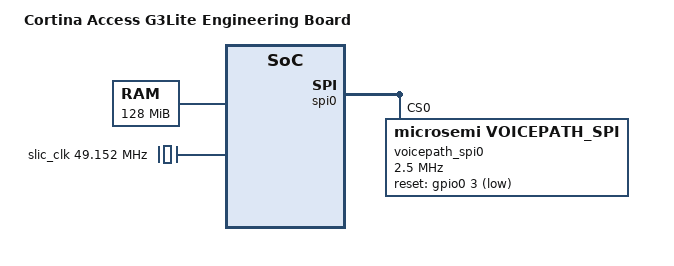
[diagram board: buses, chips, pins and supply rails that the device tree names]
/*
 * dts file for Cortina Access FPGA Development Board
 *
 * Copyright (C) 2016, Cortina Access
 *
 */

/dts-v1/;

#include <dt-bindings/gpio/gpio.h>
#include "ca76xx-soc.dtsi"
#include "ca76xx-crypto.dtsi"
#include "ca76xx-sflash.dtsi"
//#include "ca76xx-spinand.dtsi"

/* board specific and SoC overrides below */
/ {
	model = "Cortina Access G3Lite Engineering Board";
	compatible = "cortina,g3fpga";
	#address-cells = <1>;
	#size-cells = <1>;
	interrupt-parent = <&gic>;

	aliases {
		serial0 = &uart0;
	};

	memory { /* 128MB */
		device_type = "memory";
		reg = <0x00000000 0x08000000>;
	};

	ca_peri{
		compatible = "cortina,ca-peri";
		reg = <0xf4329018 0x400>,
		      <0xf4320000 0x60>;
	};

	/* APB clock varies based on G3 config */
	/* TODO: develop clock driver to switch between freq. for now use fixed freq. */
	apb_pclk: g3_apb_pclk {
		compatible = "fixed-clock";
		#clock-cells = <0>;
		clock-frequency = <125000000>;
	};

	sd_clk: g3_sd_clk {
		compatible = "fixed-clock";
		#clock-cells = <0>;
		clock-frequency = <50000000>;
	};

	slic_clk: ext_slic_clk {
		compatible = "fixed-clock";
		#clock-cells = <0>;

		/* extclk ONLY and extclk divided internally to generate sclk
		 * ISI:24576000, ZSI:49152000
		 */
		clock-frequency = <49152000>;
		clock-output-names = "ext-slic-clk";

#if 0
		/* extclk & extsclk BOTH
		 * ISI: extclk - 24576000/extsclk - 2048000
		 * ZSI: extclk - 49152000/extsclk - 2048000
		 */
		clock-frequency = <2048000>;
		clock-output-names = "ext-slic-sclk";
#endif
	};

#if 0
	/* SD clock provides 50/100/200 Mhz */
	/* TODO: develop clock driver to switch between this freq. for now use fixed freq. */
	sd_clk: g3_sd_clk {
		compatible = "fixed-clock";
		#clock-cells = <0>;
		clock-frequency = <50000000>;
	};
	/* PCIe clock provides 250 Mhz */
	pcie_clk: g3_pcie_clk {
		compatible = "fixed-clock";
		#clock-cells = <0>;
		clock-frequency = <250000000>;
	};
	/* PCIe BUS clock provides 250 Mhz */
	pcie_bclk: g3_pcie_bclk {
		compatible = "fixed-clock";
		#clock-cells = <0>;
		clock-frequency = <250000000>;
	};

	/* USB 2 clock provides 60 Mhz */
	usb2_clk: g3_usb2_clk {
		compatible = "fixed-clock";
		#clock-cells = <0>;
		clock-frequency = <60000000>;
	};

	smb { /* simple bus */

		uart0: uart@0xf4570114 {
			device_type = "serial";
			compatible = "cortina,serial";
			reg = <0xf4570114 0x30>; /* TODO - when memory map available */
			clocks = <&apb_pclk>;
			clock-names = "apb_pclk";
			interrupts = <0 32 0x1>; /* TODO - when interrupt map available */
		};

		uart1: uart@f4570144 {
			device_type = "serial";
			compatible = "cortina,serial";
			reg = <0x0 0xf4570144 0x0 0x30>; /* TODO - when memory map available */
			clocks = <&apb_pclk>;
			interrupts = <0 32 0x1>; /* edge triggered */
		};

	};
#endif

#if 0
	pon@f4329000 {
		compatible = "cortina,ca77xx-pon";
		reg = <0xf4329000 0x400>;
		pon-gpio = <&gpio0 9 GPIO_ACTIVE_LOW>;
		interrupt-parent = <&gpio0>;
		interrupts = <9 IRQ_TYPE_EDGE_RISING>;
	};
#endif

	chosen {
		bootargs = "console=ttyS0,115200 mem=128M root=/dev/mtdblock5";
	};

};

#if 0
/* "okay" - turn on, "disabled" - turn off */
&pcie0 {
	status = "disabled";
	/* ace-enable; */
	forced-gen1;
	reset-gpio = <&gpio0 0 GPIO_ACTIVE_LOW>;
};

&pcie1 {
	status = "disabled";
	/* ace-enable; */
	forced-gen1;
	reset-gpio = <&gpio0 1 GPIO_ACTIVE_LOW>;
};

&pcie2 {
	status = "disabled";
	/* ace-enable; */
	forced-gen1;
	reset-gpio = <&gpio0 2 GPIO_ACTIVE_LOW>;
};
#endif

&spi0 {
	/* explained here proslic_api/docs/ProSLIC_API_QuickStart_Linux.pdf */
#if 0
	/* Si32183: channel_count = 1, with isi, mode spi-cpha
	 * Si32285: channel_count = 2, with isi, mode spi-cpha
	 */
	proslic_spi0: proslic_spi0@0 {
		compatible = "silabs,proslic_spi", "rohm,dh2228fv";
		status = "okay";
		spi-max-frequency = <2500000>;
		reg = <0>;
		isi;
		spi-cpha;
		channel_count = <2>;
		debug_level = <7>;
		reset-gpio = <&gpio0 3 GPIO_ACTIVE_LOW>;
	};
#endif

#if 0
	/* Si32287: channel_count = 1, w/o isi, mode spi-cpha/spi-cpol */
	proslic_spi0: proslic_spi0@0 {
		compatible = "silabs,proslic_spi", "rohm,dh2228fv";
		status = "okay";
		spi-max-frequency = <2500000>;
		reg = <0>;
		spi-cpha;
		spi-cpol;
		channel_count = <2>;
		debug_level = <7>;
		reset-gpio = <&gpio0 3 GPIO_ACTIVE_LOW>;
	};
#endif

#if 1
	voicepath_spi0: voicepath_spi0@0 {
		compatible = "microsemi,voicepath_spi", "rohm,dh2228fv";
		status = "okay";
		spi-max-frequency = <2500000>;
		reg = <0>;
		zsi;
		spi-cpha;
		spi-cpol;
		spi-delay = <3>; /* 12T(pclk) */
		channel_count = <2>;
		debug_level = <7>;
		reset-gpio = <&gpio0 3 GPIO_ACTIVE_LOW>;
	};
#endif
};

&audio {
	clocks = <&slic_clk>;
};
